VERSION ""

NS_ :

BS_:

BU_: TPMS_ECU Sensor_2 Sensor_1

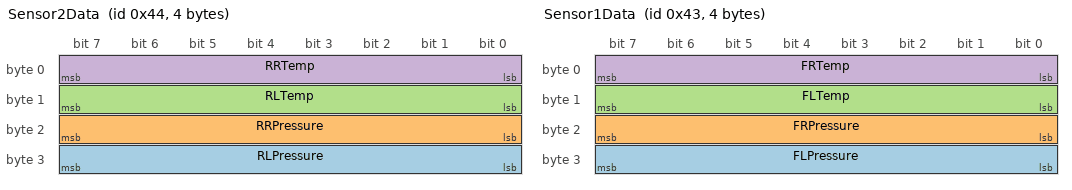
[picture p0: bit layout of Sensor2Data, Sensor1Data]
BO_ 68 Sensor2Data: 4 Sensor_2
 SG_ RLPressure : 24|8@1- (1,0) [0|0] "Psi" Vector__XXX
 SG_ RRPressure : 16|8@1- (1,0) [0|0] "Psi" Vector__XXX
 SG_ RLTemp : 8|8@1- (1,0) [0|0] "" Vector__XXX
 SG_ RRTemp : 0|8@1- (1,0) [0|0] "F" Vector__XXX

BO_ 67 Sensor1Data: 4 Sensor_1
 SG_ FLPressure : 24|8@1- (1,0) [0|0] "Psi" Vector__XXX
 SG_ FRPressure : 16|8@1- (1,0) [0|0] "Psi" Vector__XXX
 SG_ FLTemp : 8|8@1- (1,0) [0|0] "F" Vector__XXX
 SG_ FRTemp : 0|8@1- (1,0) [0|0] "" Vector__XXX

BA_DEF_  "BusType" STRING ;
BA_DEF_DEF_  "BusType" "CAN";
